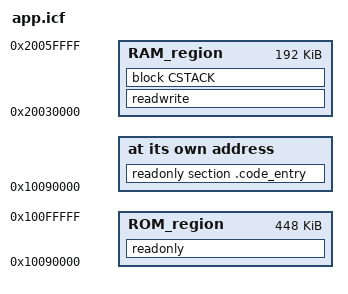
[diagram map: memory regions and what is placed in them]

define symbol __code_entry__				= 0x10090000; 			// 		代码空间 开始地址
define symbol __ICFEDIT_region_ROM_start__	= 0x10090000;  			// 320K 代码空间 开始地址
define symbol __ICFEDIT_region_ROM_end__	= 0x100FFFFF; 		// 192K	代码空间 总大小	

define symbol __region_RAM_start__			= 0x20030000;			// 内存开始地址 RAM的中间地址
define symbol __region_RAM_end__			= 0x2005ffff;			// 内存总大小	K21D=32K,K21F=64K	
define symbol __ICFEDIT_size_cstack__		= 0x00002000;			// 栈空间总大小	8K	

define memory mem with size = 4G;
define region ROM_region	= mem:[from __ICFEDIT_region_ROM_start__	to	__ICFEDIT_region_ROM_end__	];
define region RAM_region	= mem:[from __region_RAM_start__			to	__region_RAM_end__			];


define block CSTACK    with alignment = 8, size = __ICFEDIT_size_cstack__   { };

initialize by copy 						{ readwrite };
do not initialize  						{ section .noinit };
place at address mem:__code_entry__ 	{ readonly section .code_entry };
place in ROM_region   					{ readonly };
place in RAM_region   					{ readwrite, block CSTACK };
